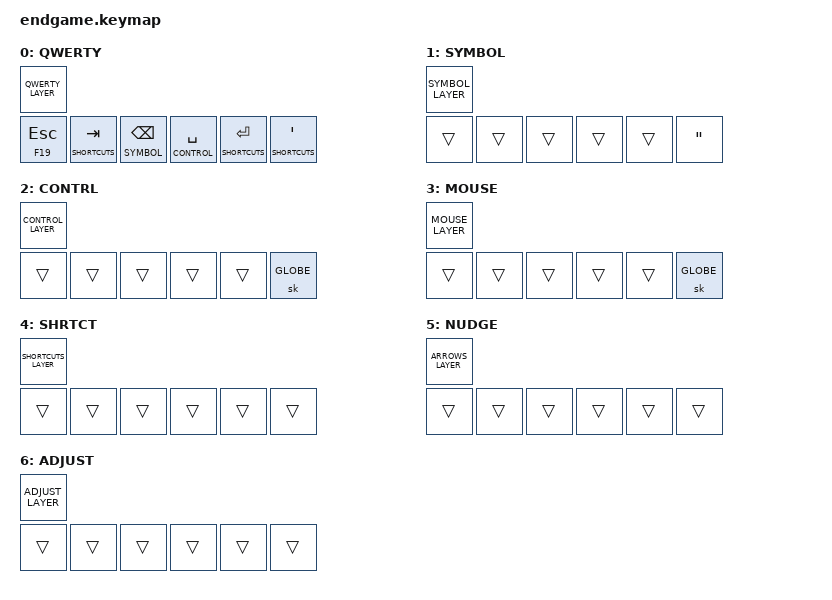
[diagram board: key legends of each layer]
/*
 * Copyright (c) 2020 The ZMK Contributors
 *
 * SPDX-License-Identifier: MIT
 */

#define ZMK_POINTING_DEFAULT_MOVE_VAL 1500

#include <behaviors.dtsi>
#include <dt-bindings/zmk/bt.h>
#include <dt-bindings/zmk/keys.h>
#include <dt-bindings/zmk/matrix_transform.h>
#include <dt-bindings/zmk/outputs.h>
#include <dt-bindings/zmk/pointing.h>
#include "shared.dtsi"

/ {
  combos {
    compatible = "zmk,combos";
    combo_space {
      timeout-ms = <50>;
      key-positions = <4 14>;
      bindings = <&kp SPC>; layers = <0>;
    };
  };

  keymap {
    compatible = "zmk,keymap";

    qwerty_layer {
      label = "QWERTY";
      bindings = <
QWERTY_LAYER
&mt F19 ESC &lt SHORTCUTS TAB &lt SYMBOL BSPC &lt CONTROL SPACE &lt SHORTCUTS RET &lt SHORTCUTS SQT
      >;
    };
    symbol_layer {
      label = "SYMBOL";
      bindings = <
SYMBOL_LAYER
&trans &trans &trans &trans &trans &kp DQT
      >;
    };

    control_layer {
      label = "CONTRL";
      bindings = <
CONTROL_LAYER
&trans &trans &trans &trans &trans &sk GLOBE
      >;
    };

    mouse_layer {
      label = "MOUSE";
      bindings = <
MOUSE_LAYER
&trans &trans &trans &trans &trans &sk GLOBE
      >;
    };

    shortcuts_layer {
      label = "SHRTCT";
      bindings = <
SHORTCUTS_LAYER
&trans &trans &trans &trans &trans &trans
      >;
    };

    arrows_layer {
      label = "NUDGE";
      bindings = <
ARROWS_LAYER
&trans &trans &trans &trans &trans &trans
      >;
    };

    adjust_layer {
      label = "ADJUST";
      bindings = <
ADJUST_LAYER
&trans &trans &trans &trans &trans &trans
      >;
   };

  };
};


